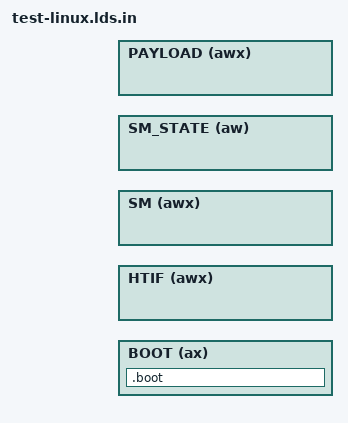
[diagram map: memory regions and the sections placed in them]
#include <parameters.h>

OUTPUT_ARCH( "riscv" )
ENTRY( sm_entry )

MEMORY
{
  BOOT (ax) :      ORIGIN = BOOT_ADDR,       LENGTH = BOOT_MAXLEN
  HTIF (awx)   :  ORIGIN = HTIF_BASE,        LENGTH = HTIF_LEN
  SM (awx) :       ORIGIN = SM_ADDR,         LENGTH = SM_LEN
  SM_STATE (aw) :  ORIGIN = SM_STATE_ADDR,   LENGTH = SM_STATE_LEN
  PAYLOAD (awx) :  ORIGIN = UNTRUSTED_ENTRY, LENGTH = PAYLOAD_MAXLEN
}

SECTIONS
{
  . = ORIGIN(BOOT);
  .boot : {
    PROVIDE( boot_entry = . );
    *(.boot.text.entry)
    *(.boot.*)
    *(.boot)
    . = ALIGN(0x8);
    _device_tree = .;
  } > BOOT =0x0
}

SECTIONS
{
  . = ORIGIN(HTIF);
  .htif ALIGN(0x1000) : {
    PROVIDE( __htif_base = . );
    *(.htif.tohost)
    *(.htif.fromhost)
  } > HTIF
}

SECTIONS
{
  . = ORIGIN(SM);
  .sm : {
    PROVIDE( sm_entry = . );
    *(.sm) /* Your payload goes here */
  } > SM =0x0
}

SECTIONS
{
  . = ORIGIN(SM_STATE);
  .sm.state : {
    *(.sm.state) /* Your payload goes here */
  } > SM_STATE =0x0
}

SECTIONS
{
  . = ORIGIN(PAYLOAD);
  .linux :{
    *(.linux)
  } > PAYLOAD =0x0

  . = IDPT_BASE;
  .idpt IDPT_BASE : {
    *(.idpt)
  } > PAYLOAD =0x0
}
